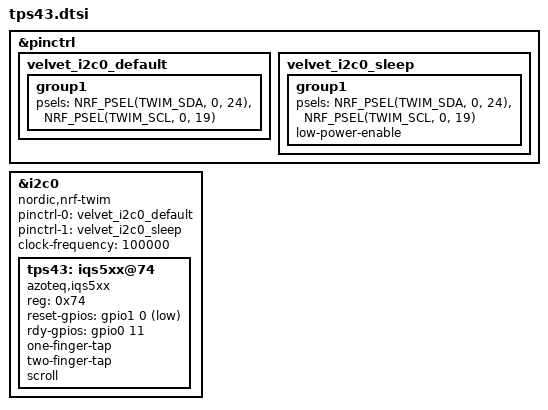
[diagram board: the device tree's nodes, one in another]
/*
 * TPS43 (Azoteq IQS5xx) trackpad on the RIGHT half (this half is the central).
 *
 * Re-uses the pins of the original PMW3610 trackball connector:
 *   SCL = P0.19  (was SPI SCK)
 *   SDA = P0.24  (was SPI MOSI/MISO)
 *   RST = P1.0   (was trackball IRQ)
 *   INT = P0.11  (was SPI CS)
 *
 * None of these pins are used by the right-half kscan matrix
 * (rows P0.10/P0.22/P0.08/P0.02, cols P1.04/P0.31/P0.29/P1.15/P1.06/P1.11).
 * The nice!view OLED uses SPI0 on P0.20/P0.17/P0.25, so there is no conflict.
 */

#include <zephyr/dt-bindings/gpio/gpio.h>

&pinctrl {
    velvet_i2c0_default: velvet_i2c0_default {
        group1 {
            psels = <NRF_PSEL(TWIM_SDA, 0, 24)>,
                    <NRF_PSEL(TWIM_SCL, 0, 19)>;
        };
    };
    velvet_i2c0_sleep: velvet_i2c0_sleep {
        group1 {
            psels = <NRF_PSEL(TWIM_SDA, 0, 24)>,
                    <NRF_PSEL(TWIM_SCL, 0, 19)>;
            low-power-enable;
        };
    };
};

&i2c0 {
    status = "okay";
    compatible = "nordic,nrf-twim";
    pinctrl-0 = <&velvet_i2c0_default>;
    pinctrl-1 = <&velvet_i2c0_sleep>;
    pinctrl-names = "default", "sleep";
    clock-frequency = <100000>;

    tps43: iqs5xx@74 {
        compatible = "azoteq,iqs5xx";
        reg = <0x74>;
        status = "okay";
        reset-gpios = <&gpio1 0 GPIO_ACTIVE_LOW>;
        rdy-gpios = <&gpio0 11 GPIO_ACTIVE_HIGH>;
        one-finger-tap;
        two-finger-tap;
        scroll;
    };
};
